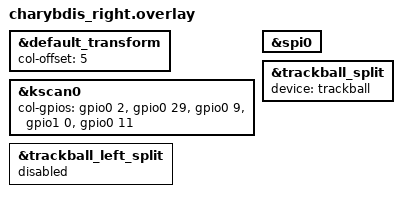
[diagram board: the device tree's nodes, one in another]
#include "charybdis.dtsi"
#include "charybdis_3610.dtsi"
#include "split_input.dtsi"

&default_transform {
	col-offset = <5>;
};	

&kscan0 {
	col-gpios
		= <&gpio0 2 (GPIO_ACTIVE_HIGH | GPIO_PULL_DOWN)>
		, <&gpio0 29 (GPIO_ACTIVE_HIGH | GPIO_PULL_DOWN)>
		, <&gpio0 9 (GPIO_ACTIVE_HIGH | GPIO_PULL_DOWN)>
		, <&gpio1 0  (GPIO_ACTIVE_HIGH | GPIO_PULL_DOWN)>
		, <&gpio0 11 (GPIO_ACTIVE_HIGH | GPIO_PULL_DOWN)>
		;
};

&spi0 {
    status = "okay";
};

&trackball_split {
    device = <&trackball>;
};

&trackball_left_split {
    status = "disabled";
};
